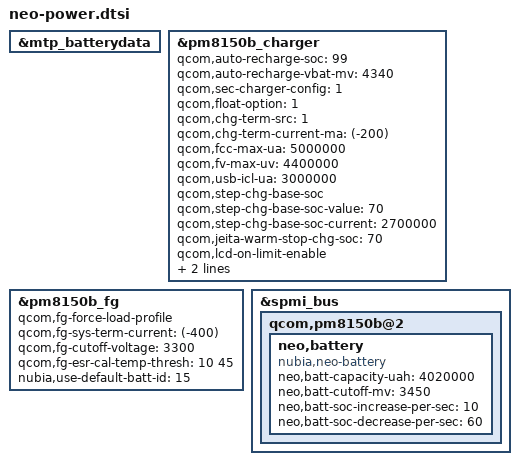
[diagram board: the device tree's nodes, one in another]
&mtp_batterydata {
	//#include "fg-gen4-batterydata-alium-3600mah-nubia.dtsi"
	#include "fg-gen4-batterydata-4000mah-nubia.dtsi"
};

&pm8150b_charger {
	qcom,auto-recharge-soc = <99>;
	qcom,auto-recharge-vbat-mv = <4340>;
	qcom,sec-charger-config = <1>;
	qcom,float-option = <1>;
	qcom,chg-term-src = <1>;
	qcom,chg-term-current-ma = <(-200)>;
	qcom,fcc-max-ua = <5000000>;
	qcom,fv-max-uv = <4400000>;
	qcom,usb-icl-ua = <3000000>;
	qcom,step-chg-base-soc;						//use nubia step soc and stop qcom sw step if specified
	qcom,step-chg-base-soc-value = <70>;		//if soc higher than this value, then reduce the fcc
	qcom,step-chg-base-soc-current = <2700000>;//the reduce the fcc value, mA
	
	qcom,jeita-warm-stop-chg-soc = <70>; //if battery is warm, stop chg when soc is higher than this threshold
	qcom,lcd-on-limit-enable;
	qcom,lcd-on-limit-temp = <400>;
	qcom,lcd-on-limit-fcc = <1200000>;
};

&pm8150b_fg {
	qcom,fg-force-load-profile;
	qcom,fg-sys-term-current = <(-400)>;
	qcom,fg-cutoff-voltage = <3300>;
	qcom,fg-esr-cal-temp-thresh = <10 45>;
	nubia,use-default-batt-id = <15>;
};


&spmi_bus {
	qcom,pm8150b@2 {
		neo,battery {
			compatible = "nubia,neo-battery";
			#address-cells = <1>;
			#size-cells = <1>;
			//reg = <0x1000 0x700>;
			neo,batt-capacity-uah = <4020000>;
			neo,batt-cutoff-mv = <3450>;
			neo,batt-soc-increase-per-sec = <10>;
			neo,batt-soc-decrease-per-sec = <60>;
		};
	};
};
